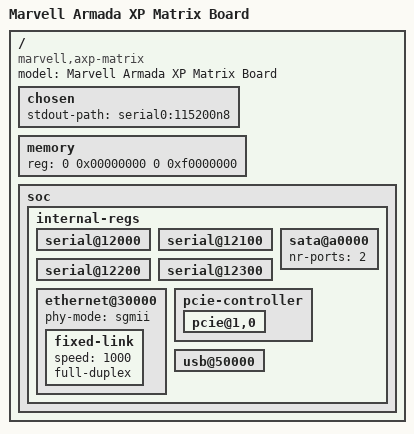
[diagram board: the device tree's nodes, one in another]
/*
 * Device Tree file for Marvell Armada XP Matrix board
 *
 * Copyright (C) 2013 Marvell
 *
 * Lior Amsalem <alior@marvell.com>
 *
 * This file is dual-licensed: you can use it either under the terms
 * of the GPL or the X11 license, at your option. Note that this dual
 * licensing only applies to this file, and not this project as a
 * whole.
 *
 *  a) This file is free software; you can redistribute it and/or
 *     modify it under the terms of the GNU General Public License as
 *     published by the Free Software Foundation; either version 2 of the
 *     License, or (at your option) any later version.
 *
 *     This file is distributed in the hope that it will be useful
 *     but WITHOUT ANY WARRANTY; without even the implied warranty of
 *     MERCHANTABILITY or FITNESS FOR A PARTICULAR PURPOSE.  See the
 *     GNU General Public License for more details.
 *
 * Or, alternatively
 *
 *  b) Permission is hereby granted, free of charge, to any person
 *     obtaining a copy of this software and associated documentation
 *     files (the "Software"), to deal in the Software without
 *     restriction, including without limitation the rights to use
 *     copy, modify, merge, publish, distribute, sublicense, and/or
 *     sell copies of the Software, and to permit persons to whom the
 *     Software is furnished to do so, subject to the following
 *     conditions:
 *
 *     The above copyright notice and this permission notice shall be
 *     included in all copies or substantial portions of the Software.
 *
 *     THE SOFTWARE IS PROVIDED , WITHOUT WARRANTY OF ANY KIND
 *     EXPRESS OR IMPLIED, INCLUDING BUT NOT LIMITED TO THE WARRANTIES
 *     OF MERCHANTABILITY, FITNESS FOR A PARTICULAR PURPOSE AND
 *     NONINFRINGEMENT. IN NO EVENT SHALL THE AUTHORS OR COPYRIGHT
 *     HOLDERS BE LIABLE FOR ANY CLAIM, DAMAGES OR OTHER LIABILITY
 *     WHETHER IN AN ACTION OF CONTRACT, TORT OR OTHERWISE, ARISING
 *     FROM, OUT OF OR IN CONNECTION WITH THE SOFTWARE OR THE USE OR
 *     OTHER DEALINGS IN THE SOFTWARE.
 */

/dts-v1/;
#include "armada-xp-mv78460.dtsi"

/ {
	model = "Marvell Armada XP Matrix Board";
	compatible = "marvell,axp-matrix", "marvell,armadaxp-mv78460", "marvell,armadaxp", "marvell,armada-370-xp";

	chosen {
		stdout-path = "serial0:115200n8";
	};

	memory {
		device_type = "memory";
		/*
		 * This board has 4 GB of RAM, but the last 256 MB of
		 * RAM are not usable due to the overlap with the MBus
		 * Window address range
		 */
		reg = <0 0x00000000 0 0xf0000000>;
	};

	soc {
		ranges = <MBUS_ID(0xf0, 0x01) 0 0 0xf1000000 0x100000
			  MBUS_ID(0x01, 0x1d) 0 0 0xfff00000 0x100000
			  MBUS_ID(0x09, 0x09) 0 0 0xf1100000 0x10000
			  MBUS_ID(0x09, 0x05) 0 0 0xf1110000 0x10000>;

		internal-regs {
			serial@12000 {
				status = "okay";
			};
			serial@12100 {
				status = "okay";
			};
			serial@12200 {
				status = "okay";
			};
			serial@12300 {
				status = "okay";
			};

			sata@a0000 {
				nr-ports = <2>;
				status = "okay";
			};

			ethernet@30000 {
				status = "okay";
				phy-mode = "sgmii";
				fixed-link {
					speed = <1000>;
					full-duplex;
				};
			};

			pcie-controller {
				status = "okay";

				pcie@1,0 {
					/* Port 0, Lane 0 */
					status = "okay";
				};
			};

			usb@50000 {
				status = "okay";
			};
		};
	};
};
